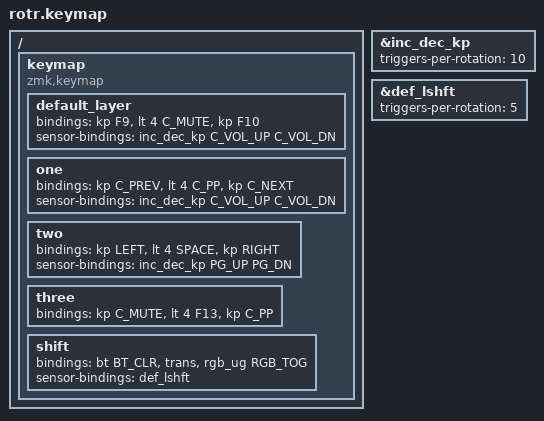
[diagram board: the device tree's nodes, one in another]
#include <behaviors.dtsi>
#include <dt-bindings/zmk/keys.h>
#include <dt-bindings/zmk/rgb.h>
#include <dt-bindings/zmk/bt.h>

&inc_dec_kp {
	triggers-per-rotation = <10>;
};
&def_lshft {
	triggers-per-rotation = <5>;
};

/ {
	keymap {
		compatible = "zmk,keymap";

		default_layer {
			//F9 | C_MUTE | F10
			bindings = <&kp F9 &lt 4 C_MUTE &kp F10>;
			sensor-bindings = <&inc_dec_kp C_VOL_UP C_VOL_DN>;
		};
		one {
			//F9 | K_MUTE | F10
			bindings = <&kp C_PREV &lt 4 C_PP &kp C_NEXT>;
			sensor-bindings = <&inc_dec_kp C_VOL_UP C_VOL_DN>;
		};
		two {
			//F9 | K_MUTE | F10
			bindings = <&kp LEFT &lt 4 SPACE &kp RIGHT>;
			sensor-bindings = <&inc_dec_kp PG_UP PG_DN>;
		};
		three {
			//F9 | K_MUTE | F10
			bindings = <&kp C_MUTE &lt 4 F13 &kp C_PP>;
		};
		shift {
			//F9 | K_MUTE | F10
			bindings = <&bt BT_CLR &trans &rgb_ug RGB_TOG>;
			sensor-bindings = <&def_lshft>;
		};
	};
};
